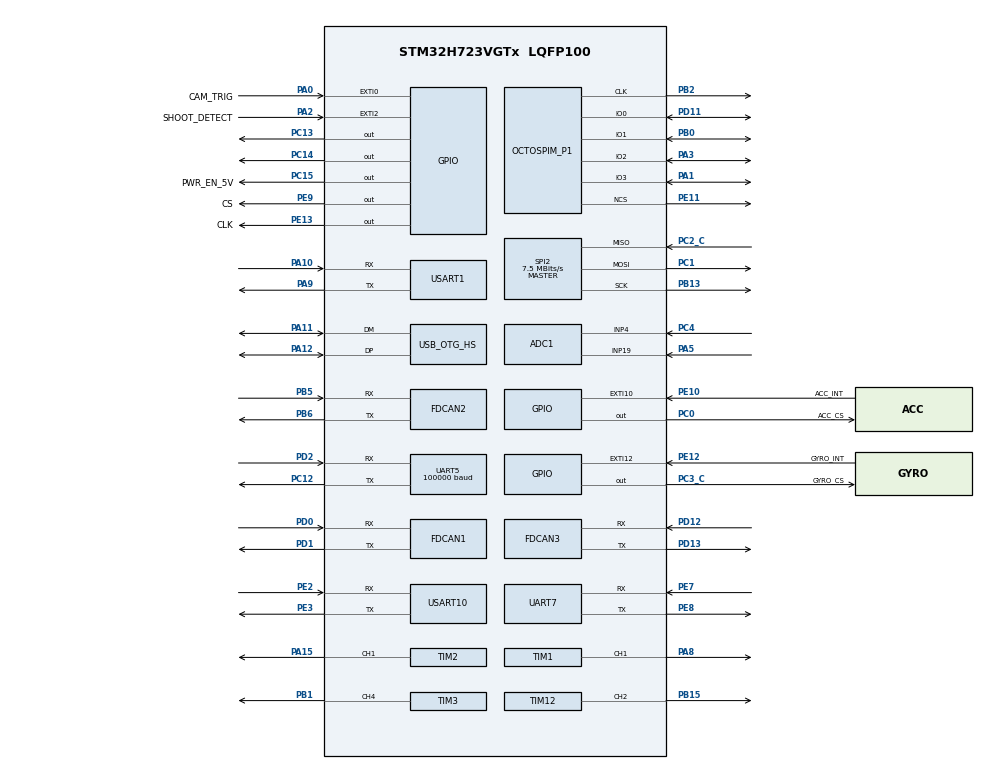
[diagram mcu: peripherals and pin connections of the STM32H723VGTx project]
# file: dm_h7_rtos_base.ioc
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ADC1.Channel-0\#ChannelRegularConversion=ADC_CHANNEL_4
ADC1.ClockPrescaler=ADC_CLOCK_ASYNC_DIV64
ADC1.ContinuousConvMode=ENABLE
ADC1.ConversionDataManagement=ADC_CONVERSIONDATA_DMA_CIRCULAR
ADC1.NbrOfConversionFlag=1
ADC1.OffsetNumber-0\#ChannelRegularConversion=ADC_OFFSET_NONE
ADC1.OffsetSignedSaturation-0\#ChannelRegularConversion=DISABLE
ADC1.Rank-0\#ChannelRegularConversion=1
ADC1.SamplingTime-0\#ChannelRegularConversion=ADC_SAMPLETIME_1CYCLE_5
ADC1.master=1
ADC3.Channel-0\#ChannelRegularConversion=ADC_CHANNEL_TEMPSENSOR
ADC3.NbrOfConversionFlag=1
ADC3.OffsetNumber-0\#ChannelRegularConversion=ADC_OFFSET_NONE
ADC3.OffsetSign-0\#ChannelRegularConversion=ADC3_OFFSET_SIGN_NEGATIVE
ADC3.Rank-0\#ChannelRegularConversion=1
ADC3.SamplingTime-0\#ChannelRegularConversion=ADC3_SAMPLETIME_640CYCLES_5
Dma.ADC1.4.Direction=DMA_PERIPH_TO_MEMORY
Dma.ADC1.4.EventEnable=DISABLE
Dma.ADC1.4.FIFOMode=DMA_FIFOMODE_DISABLE
Dma.ADC1.4.Instance=DMA1_Stream3
Dma.ADC1.4.MemDataAlignment=DMA_MDATAALIGN_HALFWORD
Dma.ADC1.4.MemInc=DMA_MINC_ENABLE
Dma.ADC1.4.Mode=DMA_CIRCULAR
Dma.ADC1.4.PeriphDataAlignment=DMA_PDATAALIGN_HALFWORD
Dma.ADC1.4.PeriphInc=DMA_PINC_DISABLE
Dma.ADC1.4.Polarity=HAL_DMAMUX_REQ_GEN_RISING
Dma.ADC1.4.Priority=DMA_PRIORITY_LOW
Dma.ADC1.4.RequestNumber=1
Dma.ADC1.4.SignalID=NONE
Dma.ADC1.4.SyncEnable=DISABLE
Dma.ADC1.4.SyncPolarity=HAL_DMAMUX_SYNC_NO_EVENT
Dma.ADC1.4.SyncRequestNumber=1
Dma.ADC1.4.SyncSignalID=NONE
Dma.Request0=SPI2_RX
Dma.Request1=SPI2_TX
Dma.Request2=USART1_RX
Dma.Request3=USART1_TX
Dma.Request4=ADC1
Dma.Request5=UART5_RX
Dma.SPI2_RX.0.Direction=DMA_PERIPH_TO_MEMORY
Dma.SPI2_RX.0.EventEnable=DISABLE
Dma.SPI2_RX.0.FIFOMode=DMA_FIFOMODE_DISABLE
Dma.SPI2_RX.0.Instance=DMA1_Stream0
Dma.SPI2_RX.0.MemDataAlignment=DMA_MDATAALIGN_BYTE
Dma.SPI2_RX.0.MemInc=DMA_MINC_ENABLE
Dma.SPI2_RX.0.Mode=DMA_NORMAL
Dma.SPI2_RX.0.PeriphDataAlignment=DMA_PDATAALIGN_BYTE
Dma.SPI2_RX.0.PeriphInc=DMA_PINC_DISABLE
Dma.SPI2_RX.0.Polarity=HAL_DMAMUX_REQ_GEN_RISING
Dma.SPI2_RX.0.Priority=DMA_PRIORITY_VERY_HIGH
Dma.SPI2_RX.0.RequestNumber=1
Dma.SPI2_RX.0.SignalID=NONE
Dma.SPI2_RX.0.SyncEnable=DISABLE
Dma.SPI2_RX.0.SyncPolarity=HAL_DMAMUX_SYNC_NO_EVENT
Dma.SPI2_RX.0.SyncRequestNumber=1
Dma.SPI2_RX.0.SyncSignalID=NONE
Dma.SPI2_TX.1.Direction=DMA_MEMORY_TO_PERIPH
Dma.SPI2_TX.1.EventEnable=DISABLE
Dma.SPI2_TX.1.FIFOMode=DMA_FIFOMODE_DISABLE
Dma.SPI2_TX.1.Instance=DMA1_Stream1
Dma.SPI2_TX.1.MemDataAlignment=DMA_MDATAALIGN_BYTE
Dma.SPI2_TX.1.MemInc=DMA_MINC_ENABLE
Dma.SPI2_TX.1.Mode=DMA_NORMAL
Dma.SPI2_TX.1.PeriphDataAlignment=DMA_PDATAALIGN_BYTE
Dma.SPI2_TX.1.PeriphInc=DMA_PINC_DISABLE
Dma.SPI2_TX.1.Polarity=HAL_DMAMUX_REQ_GEN_RISING
Dma.SPI2_TX.1.Priority=DMA_PRIORITY_HIGH
Dma.SPI2_TX.1.RequestNumber=1
Dma.SPI2_TX.1.SignalID=NONE
Dma.SPI2_TX.1.SyncEnable=DISABLE
Dma.SPI2_TX.1.SyncPolarity=HAL_DMAMUX_SYNC_NO_EVENT
Dma.SPI2_TX.1.SyncRequestNumber=1
Dma.SPI2_TX.1.SyncSignalID=NONE
Dma.UART5_RX.5.Direction=DMA_PERIPH_TO_MEMORY
Dma.UART5_RX.5.EventEnable=DISABLE
Dma.UART5_RX.5.FIFOMode=DMA_FIFOMODE_DISABLE
Dma.UART5_RX.5.Instance=DMA1_Stream5
Dma.UART5_RX.5.MemDataAlignment=DMA_MDATAALIGN_BYTE
Dma.UART5_RX.5.MemInc=DMA_MINC_ENABLE
Dma.UART5_RX.5.Mode=DMA_NORMAL
Dma.UART5_RX.5.PeriphDataAlignment=DMA_PDATAALIGN_BYTE
Dma.UART5_RX.5.PeriphInc=DMA_PINC_DISABLE
Dma.UART5_RX.5.Polarity=HAL_DMAMUX_REQ_GEN_RISING
Dma.UART5_RX.5.Priority=DMA_PRIORITY_VERY_HIGH
Dma.UART5_RX.5.RequestNumber=1
Dma.UART5_RX.5.SignalID=NONE
Dma.UART5_RX.5.SyncEnable=DISABLE
Dma.UART5_RX.5.SyncPolarity=HAL_DMAMUX_SYNC_NO_EVENT
Dma.UART5_RX.5.SyncRequestNumber=1
Dma.UART5_RX.5.SyncSignalID=NONE
Dma.USART1_RX.2.Direction=DMA_PERIPH_TO_MEMORY
Dma.USART1_RX.2.EventEnable=DISABLE
Dma.USART1_RX.2.FIFOMode=DMA_FIFOMODE_DISABLE
Dma.USART1_RX.2.Instance=DMA1_Stream2
Dma.USART1_RX.2.MemDataAlignment=DMA_MDATAALIGN_BYTE
Dma.USART1_RX.2.MemInc=DMA_MINC_ENABLE
Dma.USART1_RX.2.Mode=DMA_CIRCULAR
Dma.USART1_RX.2.PeriphDataAlignment=DMA_PDATAALIGN_BYTE
Dma.USART1_RX.2.PeriphInc=DMA_PINC_DISABLE
Dma.USART1_RX.2.Polarity=HAL_DMAMUX_REQ_GEN_RISING
Dma.USART1_RX.2.Priority=DMA_PRIORITY_LOW
Dma.USART1_RX.2.RequestNumber=1
Dma.USART1_RX.2.SignalID=NONE
Dma.USART1_RX.2.SyncEnable=DISABLE
Dma.USART1_RX.2.SyncPolarity=HAL_DMAMUX_SYNC_NO_EVENT
Dma.USART1_RX.2.SyncRequestNumber=1
Dma.USART1_RX.2.SyncSignalID=NONE
Dma.USART1_TX.3.Direction=DMA_MEMORY_TO_PERIPH
Dma.USART1_TX.3.EventEnable=DISABLE
Dma.USART1_TX.3.FIFOMode=DMA_FIFOMODE_DISABLE
Dma.USART1_TX.3.Instance=DMA1_Stream4
Dma.USART1_TX.3.MemDataAlignment=DMA_MDATAALIGN_BYTE
Dma.USART1_TX.3.MemInc=DMA_MINC_ENABLE
Dma.USART1_TX.3.Mode=DMA_NORMAL
Dma.USART1_TX.3.PeriphDataAlignment=DMA_PDATAALIGN_BYTE
Dma.USART1_TX.3.PeriphInc=DMA_PINC_DISABLE
Dma.USART1_TX.3.Polarity=HAL_DMAMUX_REQ_GEN_RISING
Dma.USART1_TX.3.Priority=DMA_PRIORITY_LOW
Dma.USART1_TX.3.RequestNumber=1
Dma.USART1_TX.3.SignalID=NONE
Dma.USART1_TX.3.SyncEnable=DISABLE
Dma.USART1_TX.3.SyncPolarity=HAL_DMAMUX_SYNC_NO_EVENT
Dma.USART1_TX.3.SyncRequestNumber=1
Dma.USART1_TX.3.SyncSignalID=NONE
FDCAN1.CalculateBaudRateNominal=1000000
FDCAN1.CalculateTimeBitNominal=1000
FDCAN1.CalculateTimeQuantumNominal=40.0
FDCAN1.DataPrescaler=3
FDCAN1.DataSyncJumpWidth=10
FDCAN1.DataTimeSeg1=29
FDCAN1.DataTimeSeg2=10
FDCAN1.ExtFiltersNbr=0
FDCAN1.NominalPrescaler=4
FDCAN1.NominalSyncJumpWidth=4
FDCAN1.NominalTimeSeg1=19
FDCAN1.NominalTimeSeg2=5
FDCAN1.ProtocolException=ENABLE
FDCAN1.RxFifo0ElmtSize=FDCAN_DATA_BYTES_8
FDCAN1.RxFifo0ElmtsNbr=8
FDCAN1.RxFifo1ElmtSize=FDCAN_DATA_BYTES_8
FDCAN1.StdFiltersNbr=1
FDCAN1.TxElmtSize=FDCAN_DATA_BYTES_8
FDCAN1.TxFifoQueueElmtsNbr=8
FDCAN2.CalculateBaudRateNominal=1000000
FDCAN2.CalculateTimeBitNominal=1000
FDCAN2.CalculateTimeQuantumNominal=50.0
FDCAN2.DataPrescaler=5
FDCAN2.DataTimeSeg1=14
FDCAN2.DataTimeSeg2=5
FDCAN2.ExtFiltersNbr=0
FDCAN2.MessageRAMOffset=854
FDCAN2.NominalPrescaler=5
FDCAN2.NominalTimeSeg1=14
FDCAN2.NominalTimeSeg2=5
FDCAN2.RxFifo0ElmtsNbr=8
FDCAN2.RxFifo1ElmtSize=FDCAN_DATA_BYTES_8
FDCAN2.RxFifo1ElmtsNbr=8
FDCAN2.StdFiltersNbr=5
FDCAN2.TxElmtSize=FDCAN_DATA_BYTES_16
FDCAN2.TxFifoQueueElmtsNbr=8
FDCAN3.CalculateBaudRateNominal=1000000
FDCAN3.CalculateTimeBitNominal=1000
FDCAN3.CalculateTimeQuantumNominal=50.0
FDCAN3.DataPrescaler=5
FDCAN3.DataTimeSeg1=14
FDCAN3.DataTimeSeg2=5
FDCAN3.ExtFiltersNbr=5
FDCAN3.MessageRAMOffset=1709
FDCAN3.NominalPrescaler=5
FDCAN3.NominalTimeSeg1=14
FDCAN3.NominalTimeSeg2=5
FDCAN3.RxFifo0ElmtsNbr=8
FDCAN3.RxFifo1ElmtsNbr=8
FDCAN3.StdFiltersNbr=5
FDCAN3.TxFifoQueueElmtsNbr=8
FREERTOS.MEMORY_ALLOCATION=0
FREERTOS.Tasks01=defaultTask,0,128,StartDefaultTask,Default,NULL,Dynamic,NULL,NULL
FREERTOS.configENABLE_FPU=1
FREERTOS.configTOTAL_HEAP_SIZE=30720
Mcu.Family=STM32H7
Mcu.Name=STM32H723VGTx
Mcu.Package=LQFP100
NVIC.DMA1_Stream0_IRQn=true\:6\:0\:true\:false\:true\:true\:false\:true\:true
NVIC.DMA1_Stream1_IRQn=true\:6\:0\:true\:false\:true\:true\:false\:true\:true
NVIC.DMA1_Stream2_IRQn=true\:5\:0\:false\:false\:true\:true\:false\:true\:true
NVIC.DMA1_Stream3_IRQn=true\:5\:0\:false\:false\:true\:true\:false\:true\:true
NVIC.DMA1_Stream4_IRQn=true\:5\:0\:false\:false\:true\:true\:false\:true\:true
NVIC.DMA1_Stream5_IRQn=true\:5\:0\:false\:false\:true\:true\:false\:true\:true
NVIC.EXTI0_IRQn=true\:5\:0\:false\:false\:true\:true\:true\:true\:true
NVIC.EXTI2_IRQn=true\:5\:0\:false\:false\:true\:true\:true\:true\:true
NVIC.FDCAN1_IT0_IRQn=true\:6\:0\:true\:false\:true\:true\:true\:true\:true
NVIC.FDCAN2_IT0_IRQn=true\:5\:0\:true\:false\:true\:true\:true\:true\:true
NVIC.FDCAN3_IT0_IRQn=true\:5\:0\:false\:false\:true\:true\:true\:true\:true
NVIC.OTG_HS_IRQn=true\:5\:0\:false\:false\:true\:true\:true\:true\:true
NVIC.PriorityGroup=NVIC_PRIORITYGROUP_4
NVIC.SPI2_IRQn=true\:5\:0\:true\:false\:true\:true\:false\:true\:true
NVIC.TIM24_IRQn=true\:5\:0\:false\:false\:true\:true\:true\:true\:true
NVIC.TIM6_DAC_IRQn=true\:15\:0\:false\:false\:true\:false\:false\:true\:true
NVIC.TimeBase=TIM6_DAC_IRQn
NVIC.TimeBaseIP=TIM6
NVIC.UART5_IRQn=true\:5\:0\:false\:false\:true\:true\:true\:true\:true
NVIC.UART7_IRQn=true\:5\:0\:false\:false\:true\:true\:true\:true\:true
NVIC.USART10_IRQn=true\:5\:0\:false\:false\:true\:true\:true\:true\:true
NVIC.USART1_IRQn=true\:5\:0\:false\:false\:true\:true\:true\:true\:true
OCTOSPI2.ChipSelectHighTime=1
OCTOSPI2.ClockMode=HAL_OSPI_CLOCK_MODE_3
OCTOSPI2.ClockPrescaler=3
OCTOSPI2.DeviceSize=23
OCTOSPI2.DeviceType=SPI_DEVICE_FLASH
OCTOSPI2.FifoThreshold=8
OCTOSPI2.SampleShifting=HAL_OSPI_SAMPLE_SHIFTING_HALFCYCLE
PA0.GPIO_Label=CAM_TRIG
PA0.Signal=GPXTI0
PA1.Mode=OCTOSPI2_IOL_Port1L
PA1.Signal=OCTOSPIM_P1_IO3
PA10.Mode=Asynchronous
PA10.Signal=USART1_RX
PA11.Mode=Device_Only_FS
PA11.Signal=USB_OTG_HS_DM
PA12.Mode=Device_Only_FS
PA12.Signal=USB_OTG_HS_DP
PA13(JTMS/SWDIO).Mode=Serial_Wire
PA13(JTMS/SWDIO).Signal=DEBUG_JTMS-SWDIO
PA14(JTCK/SWCLK).Mode=Serial_Wire
PA14(JTCK/SWCLK).Signal=DEBUG_JTCK-SWCLK
PA15(JTDI).Signal=S_TIM2_CH1_ETR
PA2.GPIO_Label=SHOOT_DETECT
PA2.GPIO_ModeDefaultEXTI=GPIO_MODE_IT_FALLING
PA2.GPIO_PuPd=GPIO_PULLUP
PA2.Signal=GPXTI2
PA3.Mode=OCTOSPI2_IOL_Port1L
PA3.Signal=OCTOSPIM_P1_IO2
PA5.Signal=ADCx_INP19
PA8.Signal=S_TIM1_CH1
PA9.Mode=Asynchronous
PA9.Signal=USART1_TX
PB0.Mode=OCTOSPI2_IOL_Port1L
PB0.Signal=OCTOSPIM_P1_IO1
PB1.Signal=S_TIM3_CH4
PB13.GPIO_Speed=GPIO_SPEED_FREQ_VERY_HIGH
PB13.Mode=Full_Duplex_Master
PB13.Signal=SPI2_SCK
PB15.Signal=S_TIM12_CH2
PB2.Mode=O2_P1_CLK
PB2.Signal=OCTOSPIM_P1_CLK
PB5.Mode=FDCAN_Activate
PB5.Signal=FDCAN2_RX
PB6.Mode=FDCAN_Activate
PB6.Signal=FDCAN2_TX
PC0.GPIO_Label=ACC_CS
PC0.GPIO_Speed=GPIO_SPEED_FREQ_VERY_HIGH
PC0.PinState=GPIO_PIN_SET
PC0.Signal=GPIO_Output
PC1.GPIO_Speed=GPIO_SPEED_FREQ_VERY_HIGH
PC1.Mode=Full_Duplex_Master
PC1.Signal=SPI2_MOSI
PC12.Mode=Asynchronous
PC12.Signal=UART5_TX
PC13.Signal=GPIO_Output
PC14-OSC32_IN.Signal=GPIO_Output
PC15-OSC32_OUT.GPIO_Label=PWR_EN_5V
PC15-OSC32_OUT.GPIO_ModeDefaultOutputPP=GPIO_MODE_OUTPUT_PP
PC15-OSC32_OUT.GPIO_PuPd=GPIO_PULLUP
PC15-OSC32_OUT.PinState=GPIO_PIN_SET
PC15-OSC32_OUT.Signal=GPIO_Output
PC2_C.GPIO_Speed=GPIO_SPEED_FREQ_VERY_HIGH
PC2_C.Mode=Full_Duplex_Master
PC2_C.Signal=SPI2_MISO
PC3_C.GPIO_Label=GYRO_CS
PC3_C.GPIO_Speed=GPIO_SPEED_FREQ_VERY_HIGH
PC3_C.PinState=GPIO_PIN_SET
PC3_C.Signal=GPIO_Output
PC4.Signal=ADCx_INP4
PD0.Mode=FDCAN_Activate
PD0.Signal=FDCAN1_RX
PD1.Mode=FDCAN_Activate
PD1.Signal=FDCAN1_TX
PD11.Mode=OCTOSPI2_IOL_Port1L
PD11.Signal=OCTOSPIM_P1_IO0
PD12.Mode=FDCAN_Activate
PD12.Signal=FDCAN3_RX
PD13.Mode=FDCAN_Activate
PD13.Signal=FDCAN3_TX
PD2.Mode=Asynchronous
PD2.Signal=UART5_RX
PE10.GPIO_Label=ACC_INT
PE10.Signal=GPXTI10
PE11.Mode=OCTOSPI2_Port1_NCS
PE11.Signal=OCTOSPIM_P1_NCS
PE12.GPIO_Label=GYRO_INT
PE12.Signal=GPXTI12
PE13.GPIO_Label=CLK
PE13.GPIO_PuPd=GPIO_PULLUP
PE13.GPIO_Speed=GPIO_SPEED_FREQ_VERY_HIGH
PE13.PinState=GPIO_PIN_SET
PE13.Signal=GPIO_Output
PE2.GPIO_PuPd=GPIO_PULLUP
PE2.Mode=Asynchronous
PE2.Signal=USART10_RX
PE3.Mode=Asynchronous
PE3.Signal=USART10_TX
PE7.Mode=Asynchronous
PE7.Signal=UART7_RX
PE8.Mode=Asynchronous
PE8.Signal=UART7_TX
PE9.GPIO_Label=CS
PE9.GPIO_PuPd=GPIO_PULLUP
PE9.GPIO_Speed=GPIO_SPEED_FREQ_VERY_HIGH
PE9.PinState=GPIO_PIN_SET
PE9.Signal=GPIO_Output
PH0-OSC_IN.Mode=HSE-External-Oscillator
PH0-OSC_IN.Signal=RCC_OSC_IN
PH1-OSC_OUT.Mode=HSE-External-Oscillator
PH1-OSC_OUT.Signal=RCC_OSC_OUT
ProjectManager.HeapSize=0x200
ProjectManager.StackSize=0x800
ProjectManager.TargetToolchain=MDK-ARM V5.32
RCC.ADCFreq_Value=100000000
RCC.APB1Freq_Value=120000000
RCC.APB2Freq_Value=120000000
RCC.APB3Freq_Value=120000000
RCC.APB4Freq_Value=120000000
RCC.CortexFreq_Value=480000000
RCC.D1PPRE=RCC_APB3_DIV2
RCC.D2PPRE1=RCC_APB1_DIV2
RCC.D2PPRE2=RCC_APB2_DIV2
RCC.D3PPRE=RCC_APB4_DIV2
RCC.DIVM1=2
RCC.DIVM2=24
RCC.DIVN1=40
RCC.DIVN2=200
RCC.DIVP1=1
RCC.FDCANCLockSelection=RCC_FDCANCLKSOURCE_PLL2
RCC.HCLKFreq_Value=240000000
RCC.HPRE=RCC_HCLK_DIV2
RCC.HSE_VALUE=24000000
RCC.PLL2FRACN=0
RCC.PLL3FRACN=0
RCC.PLLFRACN=0
RCC.PLLSourceVirtual=RCC_PLLSOURCE_HSE
RCC.SYSCLKFreq_VALUE=480000000
RCC.SYSCLKSource=RCC_SYSCLKSOURCE_PLLCLK
RCC.USBCLockSelection=RCC_USBCLKSOURCE_HSI48
RCC.USBFreq_Value=48000000
SH.ADCx_INP19.0=ADC1_INP19,IN19-Single-Ended
SH.ADCx_INP4.0=ADC1_INP4,IN4-Single-Ended
SH.S_TIM12_CH2.0=TIM12_CH2,PWM Generation2 CH2
SH.S_TIM1_CH1.0=TIM1_CH1,PWM Generation1 CH1
SH.S_TIM2_CH1_ETR.0=TIM2_CH1,PWM Generation1 CH1
SH.S_TIM3_CH4.0=TIM3_CH4,PWM Generation4 CH4
SPI2.BaudRatePrescaler=SPI_BAUDRATEPRESCALER_32
SPI2.CLKPhase=SPI_PHASE_2EDGE
SPI2.CLKPolarity=SPI_POLARITY_HIGH
SPI2.CalculateBaudRate=7.5 MBits/s
SPI2.DataSize=SPI_DATASIZE_8BIT
SPI2.Direction=SPI_DIRECTION_2LINES
SPI2.Mode=SPI_MODE_MASTER
SPI2.VirtualType=VM_MASTER
TIM1.Channel-PWM\ Generation1\ CH1=TIM_CHANNEL_1
TIM12.Channel-PWM\ Generation2\ CH2=TIM_CHANNEL_2
TIM12.Prescaler=167
TIM2.Channel-PWM\ Generation1\ CH1=TIM_CHANNEL_1
TIM2.Period=19999
TIM2.Prescaler=167
TIM2.Pulse-PWM\ Generation1\ CH1=1000
TIM24.AutoReloadPreload=TIM_AUTORELOAD_PRELOAD_ENABLE
TIM24.Prescaler=239
TIM3.AutoReloadPreload=TIM_AUTORELOAD_PRELOAD_ENABLE
TIM3.Channel-PWM\ Generation4\ CH4=TIM_CHANNEL_4
TIM3.Period=10000-1
TIM3.Prescaler=24-1
UART5.BaudRate=100000
UART5.Parity=PARITY_EVEN
UART5.StopBits=UART_STOPBITS_2
UART5.WordLength=WORDLENGTH_9B
UART7.Parity=PARITY_NONE
USART1.Parity=PARITY_NONE
USART1.VirtualMode-Asynchronous=VM_ASYNC
USART10.VirtualMode=VM_ASYNC
USB_DEVICE.CLASS_NAME_HS=CDC
USB_DEVICE.VirtualMode=Cdc
USB_DEVICE.VirtualModeHS=Cdc_HS
USB_OTG_HS.VirtualMode-Device_Only_FS=Device_Only_FS
VP_ADC3_TempSens_Input.Mode=IN-TempSens
VP_CRC_VS_CRC.Mode=CRC_Activate
VP_FREERTOS_VS_CMSIS_V2.Mode=CMSIS_V2
VP_OCTOSPI2_VS_quad.Mode=quad_mode
VP_RNG_VS_RNG.Mode=RNG_Activate
VP_SYS_VS_tim6.Mode=TIM6
VP_TIM1_VS_ClockSourceINT.Mode=Internal
VP_TIM24_VS_ClockSourceINT.Mode=Internal
VP_TIM2_VS_ClockSourceINT.Mode=Internal
VP_USB_DEVICE_VS_USB_DEVICE_CDC_HS.Mode=CDC_HS
board=custom

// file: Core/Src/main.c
/* USER CODE BEGIN Header */
/**
  ******************************************************************************
  * @file           : main.c
  * @brief          : Main program body
  ******************************************************************************
  * @attention
  *
  * Copyright (c) 2026 STMicroelectronics.
  * All rights reserved.
  *
  * This software is licensed under terms that can be found in the LICENSE file
  * in the root directory of this software component.
  * If no LICENSE file comes with this software, it is provided AS-IS.
  *
  ******************************************************************************
  */
/* USER CODE END Header */
#include "main.h"
#include "FreeRTOS.h"
#include "cmsis_os2.h"
#include "adc.h"
#include "crc.h"
#include "dma.h"
#include "fdcan.h"
#include "octospi.h"
#include "rng.h"
#include "spi.h"
#include "tim.h"
#include "usart.h"
#include "usb_device.h"
#include "gpio.h"

void SystemClock_Config(void);
void PeriphCommonClock_Config(void);
void MX_FREERTOS_Init(void);

int main(void)
{

  /* MCU Configuration--------------------------------------------------------*/

  /* Reset of all peripherals, Initializes the Flash interface and the Systick. */
  HAL_Init();

  /* Configure the system clock */
  SystemClock_Config();

  /* Configure the peripherals common clocks */
  PeriphCommonClock_Config();

  /* Initialize all configured peripherals */
  MX_GPIO_Init();
  MX_DMA_Init();
  MX_SPI2_Init();
  MX_FDCAN1_Init();
  MX_FDCAN2_Init();
  MX_TIM3_Init();
  MX_FDCAN3_Init();
  MX_USART1_UART_Init();
  MX_UART5_Init();
  MX_USART10_UART_Init();
  MX_CRC_Init();
  MX_RNG_Init();
  MX_ADC1_Init();
  MX_UART7_Init();
  MX_TIM1_Init();
  MX_TIM2_Init();
  MX_TIM12_Init();
  MX_ADC3_Init();
  MX_OCTOSPI2_Init();
  MX_TIM24_Init();
  /* USER CODE BEGIN 2 */
  /*
   * 新板（DM-MC02/CtrlBoard-H7）电源输出：
   *   PC15 PWR_EN_5V 已在 MX_GPIO_Init 中置高；
   *   PC13 Power_OUT1_EN、PC14 Power_OUT2_EN 控制两路 XT30 的 VCC_OUT，
   *   电机供电必须打开。与 DM-balanceV1 的 Power_OUT1_ON/2_ON 一致。
   */
  HAL_GPIO_WritePin(GPIOC, GPIO_PIN_13 | GPIO_PIN_14, GPIO_PIN_SET);
  /* USER CODE END 2 */

  /* Init scheduler */
  osKernelInitialize();  /* Call init function for freertos objects (in cmsis_os2.c) */
  MX_FREERTOS_Init();

  /* Start scheduler */
  osKernelStart();

  /* We should never get here as control is now taken by the scheduler */

  /* Infinite loop */
  while (1)
  {

  }
}

void SystemClock_Config(void)
{
  RCC_OscInitTypeDef RCC_OscInitStruct = {0};
  RCC_ClkInitTypeDef RCC_ClkInitStruct = {0};

  /** Supply configuration update enable
  */
  HAL_PWREx_ConfigSupply(PWR_LDO_SUPPLY);

  /** Configure the main internal regulator output voltage
  */
  __HAL_PWR_VOLTAGESCALING_CONFIG(PWR_REGULATOR_VOLTAGE_SCALE0);

  while(!__HAL_PWR_GET_FLAG(PWR_FLAG_VOSRDY)) {}

  /** Initializes the RCC Oscillators according to the specified parameters
  * in the RCC_OscInitTypeDef structure.
  */
  RCC_OscInitStruct.OscillatorType = RCC_OSCILLATORTYPE_HSI48|RCC_OSCILLATORTYPE_HSE;
  RCC_OscInitStruct.HSEState = RCC_HSE_ON;
  RCC_OscInitStruct.HSI48State = RCC_HSI48_ON;
  RCC_OscInitStruct.PLL.PLLState = RCC_PLL_ON;
  RCC_OscInitStruct.PLL.PLLSource = RCC_PLLSOURCE_HSE;
  RCC_OscInitStruct.PLL.PLLM = 2;
  RCC_OscInitStruct.PLL.PLLN = 40;
  RCC_OscInitStruct.PLL.PLLP = 1;
  RCC_OscInitStruct.PLL.PLLQ = 2;
  RCC_OscInitStruct.PLL.PLLR = 2;
  RCC_OscInitStruct.PLL.PLLRGE = RCC_PLL1VCIRANGE_3;
  RCC_OscInitStruct.PLL.PLLVCOSEL = RCC_PLL1VCOWIDE;
  RCC_OscInitStruct.PLL.PLLFRACN = 0;
  if (HAL_RCC_OscConfig(&RCC_OscInitStruct) != HAL_OK)
  {
    Error_Handler();
  }

  /** Initializes the CPU, AHB and APB buses clocks
  */
  RCC_ClkInitStruct.ClockType = RCC_CLOCKTYPE_HCLK|RCC_CLOCKTYPE_SYSCLK
                              |RCC_CLOCKTYPE_PCLK1|RCC_CLOCKTYPE_PCLK2
                              |RCC_CLOCKTYPE_D3PCLK1|RCC_CLOCKTYPE_D1PCLK1;
  RCC_ClkInitStruct.SYSCLKSource = RCC_SYSCLKSOURCE_PLLCLK;
  RCC_ClkInitStruct.SYSCLKDivider = RCC_SYSCLK_DIV1;
  RCC_ClkInitStruct.AHBCLKDivider = RCC_HCLK_DIV2;
  RCC_ClkInitStruct.APB3CLKDivider = RCC_APB3_DIV2;
  RCC_ClkInitStruct.APB1CLKDivider = RCC_APB1_DIV2;
  RCC_ClkInitStruct.APB2CLKDivider = RCC_APB2_DIV2;
  RCC_ClkInitStruct.APB4CLKDivider = RCC_APB4_DIV2;

  if (HAL_RCC_ClockConfig(&RCC_ClkInitStruct, FLASH_LATENCY_3) != HAL_OK)
  {
    Error_Handler();
  }
}

void PeriphCommonClock_Config(void)
{
  RCC_PeriphCLKInitTypeDef PeriphClkInitStruct = {0};

  /** Initializes the peripherals clock
  */
  PeriphClkInitStruct.PeriphClockSelection = RCC_PERIPHCLK_ADC|RCC_PERIPHCLK_FDCAN;
  PeriphClkInitStruct.PLL2.PLL2M = 24;
  PeriphClkInitStruct.PLL2.PLL2N = 200;
  PeriphClkInitStruct.PLL2.PLL2P = 2;
  PeriphClkInitStruct.PLL2.PLL2Q = 2;
  PeriphClkInitStruct.PLL2.PLL2R = 2;
  PeriphClkInitStruct.PLL2.PLL2RGE = RCC_PLL2VCIRANGE_0;
  PeriphClkInitStruct.PLL2.PLL2VCOSEL = RCC_PLL2VCOMEDIUM;
  PeriphClkInitStruct.PLL2.PLL2FRACN = 0;
  PeriphClkInitStruct.FdcanClockSelection = RCC_FDCANCLKSOURCE_PLL2;
  PeriphClkInitStruct.AdcClockSelection = RCC_ADCCLKSOURCE_PLL2;
  if (HAL_RCCEx_PeriphCLKConfig(&PeriphClkInitStruct) != HAL_OK)
  {
    Error_Handler();
  }
}

void HAL_TIM_PeriodElapsedCallback(TIM_HandleTypeDef *htim)
{
  if (htim->Instance == TIM6)
  {
    HAL_IncTick();
  }
}

void Error_Handler(void)
{
  __disable_irq();
  while (1)
  {
  }
}

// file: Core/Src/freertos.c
/* USER CODE BEGIN Header */
/**
  ******************************************************************************
  * File Name          : freertos.c
  * Description        : Code for freertos applications
  ******************************************************************************
  * @attention
  *
  * Copyright (c) 2026 STMicroelectronics.
  * All rights reserved.
  *
  * This software is licensed under terms that can be found in the LICENSE file
  * in the root directory of this software component.
  * If no LICENSE file comes with this software, it is provided AS-IS.
  *
  ******************************************************************************
  */
/* USER CODE END Header */

#include "FreeRTOS.h"
#include "task.h"
#include "main.h"
#include "FreeRTOS.h"
#include "cmsis_os2.h"

/* USER CODE BEGIN Includes */
#include "app_chassis_board.h"
/* USER CODE END Includes */

/* USER CODE BEGIN Variables */
osThreadId_t chassisTaskHandle;
const osThreadAttr_t chassisTask_attributes = {
  .name = "chassisTask",
  .stack_size = 128 * 32,
  .priority = (osPriority_t) osPriorityHigh,
};
/* USER CODE END Variables */
/* Definitions for defaultTask */
osThreadId_t defaultTaskHandle;
const osThreadAttr_t defaultTask_attributes = {
  .name = "defaultTask",
  .stack_size = 128 * 4,
  .priority = (osPriority_t) osPriorityNormal,
};

void StartDefaultTask(void *argument);

extern void MX_USB_DEVICE_Init(void);
void MX_FREERTOS_Init(void); /* (MISRA C 2004 rule 8.1) */

void MX_FREERTOS_Init(void) {

  /* Create the thread(s) */
  /* creation of defaultTask */
  defaultTaskHandle = osThreadNew(StartDefaultTask, NULL, &defaultTask_attributes);

  /* USER CODE BEGIN RTOS_THREADS */
#if chassis_board_task
  chassisTaskHandle = osThreadNew(chassis_task, NULL, &chassisTask_attributes);
#endif
  /* USER CODE END RTOS_THREADS */

}

void StartDefaultTask(void *argument)
{
  /* init code for USB_DEVICE */
  MX_USB_DEVICE_Init();
  for(;;)
  {
    osDelay(1);
  }
}
